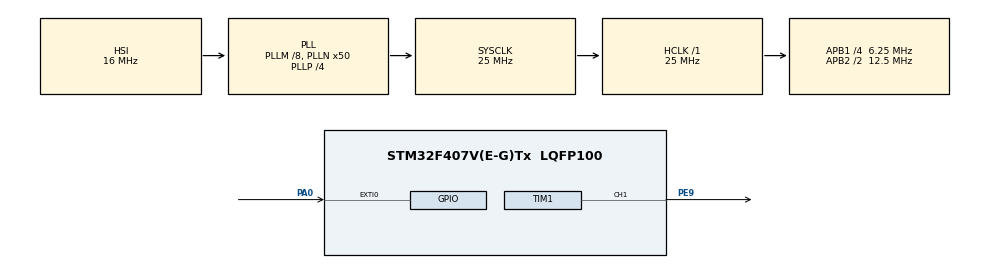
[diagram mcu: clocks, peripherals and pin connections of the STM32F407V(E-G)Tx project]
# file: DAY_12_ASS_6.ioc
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Mcu.Family=STM32F4
Mcu.Name=STM32F407V(E-G)Tx
Mcu.Package=LQFP100
NVIC.EXTI0_IRQn=true\:0\:0\:false\:false\:true\:true\:true\:true
NVIC.PriorityGroup=NVIC_PRIORITYGROUP_0
PA0-WKUP.Signal=GPXTI0
PE9.Signal=S_TIM1_CH1
ProjectManager.HeapSize=0x200
ProjectManager.StackSize=0x400
ProjectManager.TargetToolchain=STM32CubeIDE
RCC.48MHZClocksFreq_Value=14285714.285714285
RCC.AHBFreq_Value=25000000
RCC.APB1CLKDivider=RCC_HCLK_DIV4
RCC.APB1Freq_Value=6250000
RCC.APB1TimFreq_Value=12500000
RCC.APB2CLKDivider=RCC_HCLK_DIV2
RCC.APB2Freq_Value=12500000
RCC.APB2TimFreq_Value=25000000
RCC.CortexFreq_Value=25000000
RCC.HCLKFreq_Value=25000000
RCC.HSE_VALUE=8000000
RCC.HSI_VALUE=16000000
RCC.LSE_VALUE=32768
RCC.PLLM=8
RCC.PLLN=50
RCC.PLLP=RCC_PLLP_DIV4
RCC.PLLQ=7
RCC.SYSCLKFreq_VALUE=25000000
RCC.SYSCLKSource=RCC_SYSCLKSOURCE_PLLCLK
RCC.VCOOutputFreq_Value=100000000
SH.S_TIM1_CH1.0=TIM1_CH1,PWM Generation1 CH1
TIM1.Channel-PWM\ Generation1\ CH1=TIM_CHANNEL_1
TIM1.Period=99
TIM1.Prescaler=24
VP_TIM1_VS_ClockSourceINT.Mode=Internal
board=STM32F407G-DISC1

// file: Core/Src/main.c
/* USER CODE BEGIN Header */
/**
  ******************************************************************************
  * @file           : main.c
  * @brief          : Main program body
  ******************************************************************************
  * @attention
  *
  * Copyright (c) 2026 STMicroelectronics.
  * All rights reserved.
  *
  * This software is licensed under terms that can be found in the LICENSE file
  * in the root directory of this software component.
  * If no LICENSE file comes with this software, it is provided AS-IS.
  *
  ******************************************************************************
  */
/* USER CODE END Header */
#include "main.h"

TIM_HandleTypeDef htim1;

void SystemClock_Config(void);
static void MX_GPIO_Init(void);
static void MX_TIM1_Init(void);

/* USER CODE BEGIN 0 */
volatile uint8_t brightness = 0;
/* USER CODE END 0 */

int main(void)
{

  /* MCU Configuration--------------------------------------------------------*/

  /* Reset of all peripherals, Initializes the Flash interface and the Systick. */
  HAL_Init();

  /* Configure the system clock */
  SystemClock_Config();

  /* Initialize all configured peripherals */
  MX_GPIO_Init();
  MX_TIM1_Init();
  /* USER CODE BEGIN 2 */
  HAL_TIM_PWM_Start(&htim1, TIM_CHANNEL_1);
  htim1.Instance->CCR1 = 0;
  /* USER CODE END 2 */

  /* Infinite loop */
  while (1)
  {

  }
}

void SystemClock_Config(void)
{
  RCC_OscInitTypeDef RCC_OscInitStruct = {0};
  RCC_ClkInitTypeDef RCC_ClkInitStruct = {0};

  /** Configure the main internal regulator output voltage
  */
  __HAL_RCC_PWR_CLK_ENABLE();
  __HAL_PWR_VOLTAGESCALING_CONFIG(PWR_REGULATOR_VOLTAGE_SCALE1);

  /** Initializes the RCC Oscillators according to the specified parameters
  * in the RCC_OscInitTypeDef structure.
  */
  RCC_OscInitStruct.OscillatorType = RCC_OSCILLATORTYPE_HSI;
  RCC_OscInitStruct.HSIState = RCC_HSI_ON;
  RCC_OscInitStruct.HSICalibrationValue = RCC_HSICALIBRATION_DEFAULT;
  RCC_OscInitStruct.PLL.PLLState = RCC_PLL_ON;
  RCC_OscInitStruct.PLL.PLLSource = RCC_PLLSOURCE_HSI;
  RCC_OscInitStruct.PLL.PLLM = 8;
  RCC_OscInitStruct.PLL.PLLN = 50;
  RCC_OscInitStruct.PLL.PLLP = RCC_PLLP_DIV4;
  RCC_OscInitStruct.PLL.PLLQ = 7;
  if (HAL_RCC_OscConfig(&RCC_OscInitStruct) != HAL_OK)
  {
    Error_Handler();
  }

  /** Initializes the CPU, AHB and APB buses clocks
  */
  RCC_ClkInitStruct.ClockType = RCC_CLOCKTYPE_HCLK|RCC_CLOCKTYPE_SYSCLK
                              |RCC_CLOCKTYPE_PCLK1|RCC_CLOCKTYPE_PCLK2;
  RCC_ClkInitStruct.SYSCLKSource = RCC_SYSCLKSOURCE_PLLCLK;
  RCC_ClkInitStruct.AHBCLKDivider = RCC_SYSCLK_DIV1;
  RCC_ClkInitStruct.APB1CLKDivider = RCC_HCLK_DIV4;
  RCC_ClkInitStruct.APB2CLKDivider = RCC_HCLK_DIV2;

  if (HAL_RCC_ClockConfig(&RCC_ClkInitStruct, FLASH_LATENCY_0) != HAL_OK)
  {
    Error_Handler();
  }
}

static void MX_TIM1_Init(void)
{

  TIM_ClockConfigTypeDef sClockSourceConfig = {0};
  TIM_MasterConfigTypeDef sMasterConfig = {0};
  TIM_OC_InitTypeDef sConfigOC = {0};
  TIM_BreakDeadTimeConfigTypeDef sBreakDeadTimeConfig = {0};

  htim1.Instance = TIM1;
  htim1.Init.Prescaler = 24;
  htim1.Init.CounterMode = TIM_COUNTERMODE_UP;
  htim1.Init.Period = 99;
  htim1.Init.ClockDivision = TIM_CLOCKDIVISION_DIV1;
  htim1.Init.RepetitionCounter = 0;
  htim1.Init.AutoReloadPreload = TIM_AUTORELOAD_PRELOAD_DISABLE;
  if (HAL_TIM_Base_Init(&htim1) != HAL_OK)
  {
    Error_Handler();
  }
  sClockSourceConfig.ClockSource = TIM_CLOCKSOURCE_INTERNAL;
  if (HAL_TIM_ConfigClockSource(&htim1, &sClockSourceConfig) != HAL_OK)
  {
    Error_Handler();
  }
  if (HAL_TIM_PWM_Init(&htim1) != HAL_OK)
  {
    Error_Handler();
  }
  sMasterConfig.MasterOutputTrigger = TIM_TRGO_RESET;
  sMasterConfig.MasterSlaveMode = TIM_MASTERSLAVEMODE_DISABLE;
  if (HAL_TIMEx_MasterConfigSynchronization(&htim1, &sMasterConfig) != HAL_OK)
  {
    Error_Handler();
  }
  sConfigOC.OCMode = TIM_OCMODE_PWM1;
  sConfigOC.Pulse = 0;
  sConfigOC.OCPolarity = TIM_OCPOLARITY_HIGH;
  sConfigOC.OCNPolarity = TIM_OCNPOLARITY_HIGH;
  sConfigOC.OCFastMode = TIM_OCFAST_DISABLE;
  sConfigOC.OCIdleState = TIM_OCIDLESTATE_RESET;
  sConfigOC.OCNIdleState = TIM_OCNIDLESTATE_RESET;
  if (HAL_TIM_PWM_ConfigChannel(&htim1, &sConfigOC, TIM_CHANNEL_1) != HAL_OK)
  {
    Error_Handler();
  }
  sBreakDeadTimeConfig.OffStateRunMode = TIM_OSSR_DISABLE;
  sBreakDeadTimeConfig.OffStateIDLEMode = TIM_OSSI_DISABLE;
  sBreakDeadTimeConfig.LockLevel = TIM_LOCKLEVEL_OFF;
  sBreakDeadTimeConfig.DeadTime = 0;
  sBreakDeadTimeConfig.BreakState = TIM_BREAK_DISABLE;
  sBreakDeadTimeConfig.BreakPolarity = TIM_BREAKPOLARITY_HIGH;
  sBreakDeadTimeConfig.AutomaticOutput = TIM_AUTOMATICOUTPUT_DISABLE;
  if (HAL_TIMEx_ConfigBreakDeadTime(&htim1, &sBreakDeadTimeConfig) != HAL_OK)
  {
    Error_Handler();
  }
  HAL_TIM_MspPostInit(&htim1);

}

static void MX_GPIO_Init(void)
{
  GPIO_InitTypeDef GPIO_InitStruct = {0};

  /* GPIO Ports Clock Enable */
  __HAL_RCC_GPIOA_CLK_ENABLE();
  __HAL_RCC_GPIOE_CLK_ENABLE();

  /*Configure GPIO pin : PA0 */
  GPIO_InitStruct.Pin = GPIO_PIN_0;
  GPIO_InitStruct.Mode = GPIO_MODE_IT_RISING;
  GPIO_InitStruct.Pull = GPIO_NOPULL;
  HAL_GPIO_Init(GPIOA, &GPIO_InitStruct);

  /* EXTI interrupt init*/
  HAL_NVIC_SetPriority(EXTI0_IRQn, 0, 0);
  HAL_NVIC_EnableIRQ(EXTI0_IRQn);

}

/* USER CODE BEGIN 4 */
void HAL_GPIO_EXTI_Callback(uint16_t GPIO_Pin)
{
    if(GPIO_Pin == GPIO_PIN_0)
    {
        brightness += 25;

        if(brightness > 100)
        {
            brightness = 0;
        }

        htim1.Instance->CCR1 = brightness;
    }
}
/* USER CODE END 4 */

void Error_Handler(void)
{
  __disable_irq();
  while (1)
  {
  }
}
